CM_ "IMPORT _honda_common.dbc";
CM_ "IMPORT _nidec_common.dbc";
CM_ "IMPORT _lkas_hud_5byte.dbc";
CM_ "IMPORT _nidec_scm_group_a.dbc";
CM_ "IMPORT _steering_sensors_b.dbc";
CM_ "IMPORT _gearbox_common.dbc";

CM_ "The RLX EPS uses the 4 byte STEERING_CONTROL of _steering_control_b.dbc with the 7 byte STEER_STATUS of _steering_control_a.dbc";
CM_ "Both live on a separate steer bus and are bridged to the powertrain bus by a panda running the hondaRlxForwarder safety mode";

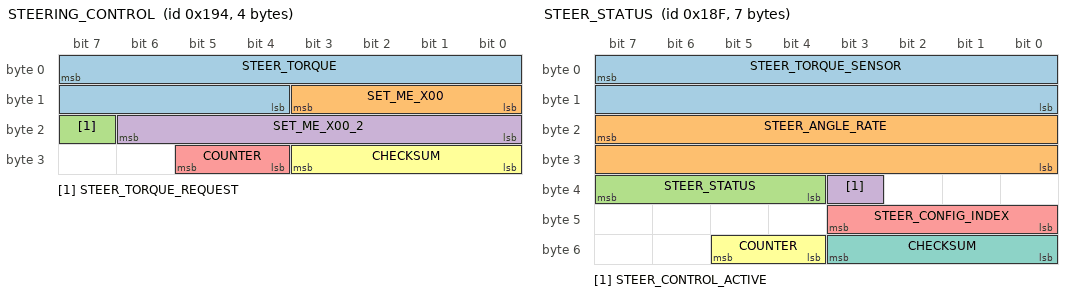
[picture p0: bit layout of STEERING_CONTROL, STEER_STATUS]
BO_ 404 STEERING_CONTROL: 4 EON
 SG_ STEER_TORQUE : 7|12@0- (1,0) [-768|768] "" EPS
 SG_ SET_ME_X00 : 11|4@0+ (1,0) [0|15] "" EPS
 SG_ STEER_TORQUE_REQUEST : 23|1@0+ (1,0) [0|1] "" EPS
 SG_ SET_ME_X00_2 : 22|7@0+ (1,0) [0|127] "" EPS
 SG_ COUNTER : 29|2@0+ (1,0) [0|15] "" EPS
 SG_ CHECKSUM : 27|4@0+ (1,0) [0|3] "" EPS

BO_ 399 STEER_STATUS: 7 EPS
 SG_ STEER_TORQUE_SENSOR : 7|16@0- (-1,0) [-31000|31000] "tbd" EON
 SG_ STEER_ANGLE_RATE : 23|16@0- (-0.1,0) [-31000|31000] "deg/s" EON
 SG_ STEER_STATUS : 39|4@0+ (1,0) [0|15] "" EON
 SG_ STEER_CONTROL_ACTIVE : 35|1@0+ (1,0) [0|1] "" EON
 SG_ STEER_CONFIG_INDEX : 43|4@0+ (1,0) [0|15] "" EON
 SG_ COUNTER : 53|2@0+ (1,0) [0|3] "" EON
 SG_ CHECKSUM : 51|4@0+ (1,0) [0|3] "" EON

VAL_ 399 STEER_STATUS 7 "permanent_fault" 6 "tmp_fault" 5 "fault_1" 4 "no_torque_alert_2" 3 "low_speed_lockout" 2 "no_torque_alert_1" 1 "driver_steering" 0 "normal" ;
